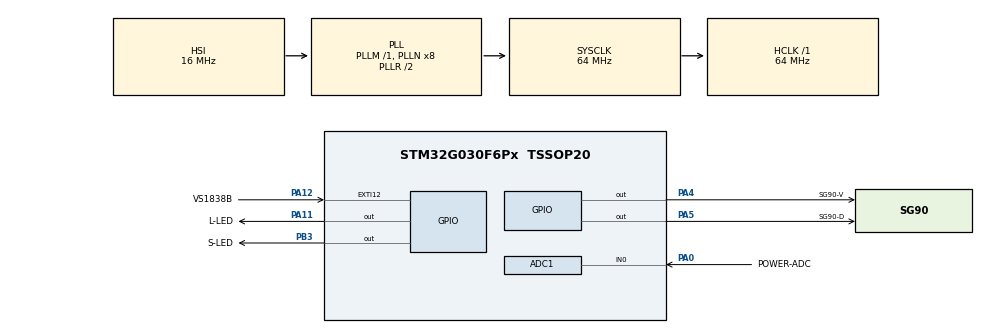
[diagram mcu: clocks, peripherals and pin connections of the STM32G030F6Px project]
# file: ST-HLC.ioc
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ADC1.Channel-0\#ChannelRegularConversion=ADC_CHANNEL_0
ADC1.NbrOfConversionFlag=1
ADC1.Rank-0\#ChannelRegularConversion=1
ADC1.SamplingTime-0\#ChannelRegularConversion=ADC_SAMPLINGTIME_COMMON_1
ADC1.SelectedChannel=ADC_CHANNEL_0
ADC1.master=1
Mcu.Family=STM32G0
Mcu.Name=STM32G030F6Px
Mcu.Package=TSSOP20
PA0.GPIO_Label=POWER-ADC
PA0.Mode=IN0
PA0.Signal=ADC1_IN0
PA11\ [PA9].GPIO_Label=L-LED
PA11\ [PA9].Signal=GPIO_Output
PA12\ [PA10].GPIO_Label=VS1838B
PA12\ [PA10].GPIO_ModeDefaultEXTI=GPIO_MODE_IT_FALLING
PA12\ [PA10].GPIO_PuPd=GPIO_NOPULL
PA12\ [PA10].Signal=GPXTI12
PA13.Mode=Serial_Wire
PA13.Signal=SYS_SWDIO
PA14-BOOT0.Mode=Serial_Wire
PA14-BOOT0.Signal=SYS_SWCLK
PA14-BOOT0__PA15.StandardMode=true
PA4.GPIO_Label=SG90-V
PA4.GPIO_ModeDefaultOutputPP=GPIO_MODE_OUTPUT_OD
PA4.GPIO_PuPd=GPIO_PULLUP
PA4.PinState=GPIO_PIN_RESET
PA4.Signal=GPIO_Output
PA5.GPIO_Label=SG90-D
PA5.PinState=GPIO_PIN_SET
PA5.Signal=GPIO_Output
PB0__PB1__PB2__PA8.StandardMode=true
PB3.GPIO_Label=S-LED
PB3.GPIO_PuPd=GPIO_NOPULL
PB3.Signal=GPIO_Output
PB3__PB4__PB5__PB6.StandardMode=true
PB7__PB8.StandardMode=true
PC14-OSC32_IN\ (PC14)__PB9.StandardMode=true
ProjectManager.HeapSize=0x200
ProjectManager.StackSize=0x400
ProjectManager.TargetToolchain=STM32CubeIDE
RCC.ADCFreq_Value=64000000
RCC.AHBFreq_Value=64000000
RCC.CortexFreq_Value=64000000
RCC.EXTERNAL_CLOCK_VALUE=12288000
RCC.HCLKFreq_Value=64000000
RCC.HSE_VALUE=8000000
RCC.HSI_VALUE=16000000
RCC.LSE_VALUE=32768
RCC.SYSCLKFreq_VALUE=64000000
RCC.SYSCLKSource=RCC_SYSCLKSOURCE_PLLCLK
RCC.VCOOutputFreq_Value=128000000
TIM1.AutoReloadPreload=TIM_AUTORELOAD_PRELOAD_DISABLE
TIM1.Period=65535
TIM1.Prescaler=63
VP_TIM1_VS_ClockSourceINT.Mode=Internal
board=custom

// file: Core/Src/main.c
/* USER CODE BEGIN Header */
/**
  ******************************************************************************
  * @file           : main.c
  * @brief          : Main program body
  ******************************************************************************
  * @attention
  *
  * Copyright (c) 2023 STMicroelectronics.
  * All rights reserved.
  *
  * This software is licensed under terms that can be found in the LICENSE file
  * in the root directory of this software component.
  * If no LICENSE file comes with this software, it is provided AS-IS.
  *
  ******************************************************************************
  */
/* USER CODE END Header */
#include "main.h"
#include "adc.h"
#include "tim.h"
#include "gpio.h"

/* USER CODE BEGIN Includes */
#include "service_main.h"
/* USER CODE END Includes */

void SystemClock_Config(void);

int main(void)
{

  /* MCU Configuration--------------------------------------------------------*/

  /* Reset of all peripherals, Initializes the Flash interface and the Systick. */
  HAL_Init();

  /* Configure the system clock */
  SystemClock_Config();

  /* Initialize all configured peripherals */
  MX_GPIO_Init();
  MX_ADC1_Init();
  MX_TIM1_Init();
  /* USER CODE BEGIN 2 */
    Main_Init();
  /* USER CODE END 2 */

  /* Infinite loop */
  /* USER CODE BEGIN WHILE */
    while (1) {
        Main_RUN();
    /* USER CODE END WHILE */

    }
}

void SystemClock_Config(void)
{
  RCC_OscInitTypeDef RCC_OscInitStruct = {0};
  RCC_ClkInitTypeDef RCC_ClkInitStruct = {0};

  /** Configure the main internal regulator output voltage
  */
  HAL_PWREx_ControlVoltageScaling(PWR_REGULATOR_VOLTAGE_SCALE1);

  /** Initializes the RCC Oscillators according to the specified parameters
  * in the RCC_OscInitTypeDef structure.
  */
  RCC_OscInitStruct.OscillatorType = RCC_OSCILLATORTYPE_HSI;
  RCC_OscInitStruct.HSIState = RCC_HSI_ON;
  RCC_OscInitStruct.HSIDiv = RCC_HSI_DIV1;
  RCC_OscInitStruct.HSICalibrationValue = RCC_HSICALIBRATION_DEFAULT;
  RCC_OscInitStruct.PLL.PLLState = RCC_PLL_ON;
  RCC_OscInitStruct.PLL.PLLSource = RCC_PLLSOURCE_HSI;
  RCC_OscInitStruct.PLL.PLLM = RCC_PLLM_DIV1;
  RCC_OscInitStruct.PLL.PLLN = 8;
  RCC_OscInitStruct.PLL.PLLP = RCC_PLLP_DIV2;
  RCC_OscInitStruct.PLL.PLLR = RCC_PLLR_DIV2;
  if (HAL_RCC_OscConfig(&RCC_OscInitStruct) != HAL_OK)
  {
    Error_Handler();
  }

  /** Initializes the CPU, AHB and APB buses clocks
  */
  RCC_ClkInitStruct.ClockType = RCC_CLOCKTYPE_HCLK|RCC_CLOCKTYPE_SYSCLK
                              |RCC_CLOCKTYPE_PCLK1;
  RCC_ClkInitStruct.SYSCLKSource = RCC_SYSCLKSOURCE_PLLCLK;
  RCC_ClkInitStruct.AHBCLKDivider = RCC_SYSCLK_DIV1;
  RCC_ClkInitStruct.APB1CLKDivider = RCC_HCLK_DIV1;

  if (HAL_RCC_ClockConfig(&RCC_ClkInitStruct, FLASH_LATENCY_2) != HAL_OK)
  {
    Error_Handler();
  }
}

void Error_Handler(void)
{
    __disable_irq();
    while (1) {
    }
}
